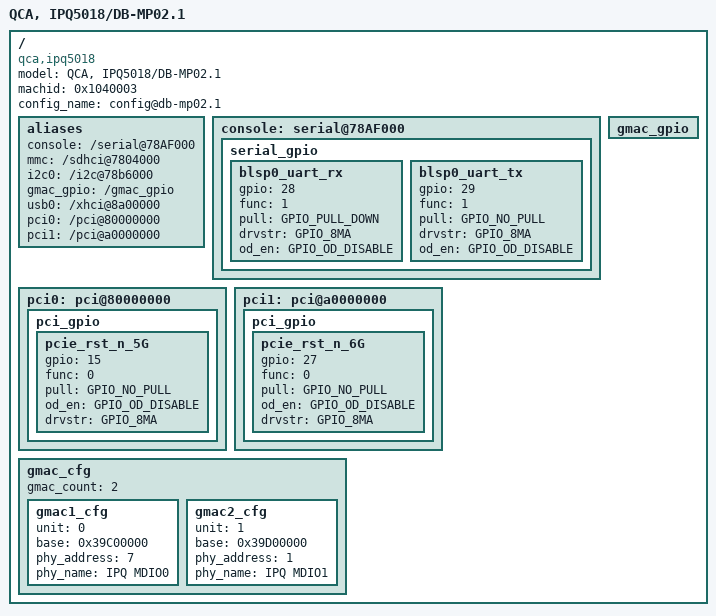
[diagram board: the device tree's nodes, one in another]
/*
 * Copyright (c) 2016-2020, The Linux Foundation. All rights reserved.
 *
 * This program is free software; you can redistribute it and/or modify
 * it under the terms of the GNU General Public License version 2 and
 * only version 2 as published by the Free Software Foundation.
 *
 * This program is distributed in the hope that it will be useful,
 * but WITHOUT ANY WARRANTY; without even the implied warranty of
 * MERCHANTABILITY or FITNESS FOR A PARTICULAR PURPOSE.  See the
 * GNU General Public License for more details.
 */

/dts-v1/;
#include "ipq5018-soc.dtsi"
/ {
	model ="QCA, IPQ5018/DB-MP02.1";
	compatible = "qca,ipq5018", "qca,ipq5018-db-mp02.1";
	machid = <0x1040003>;
	config_name = "config@db-mp02.1";

	aliases {
		console = "/serial@78AF000";
		mmc = "/sdhci@7804000";
		i2c0 = "/i2c@78b6000";
		gmac_gpio = "/gmac_gpio";
		usb0 = "/xhci@8a00000";
		pci0 = "/pci@80000000";
		pci1 = "/pci@a0000000";
	};

	console: serial@78AF000 {
		status = "ok";
		serial_gpio {
			blsp0_uart_rx {
				gpio = <28>;
				func = <1>;
				pull = <GPIO_PULL_DOWN>;
				drvstr = <GPIO_8MA>;
				od_en = <GPIO_OD_DISABLE>;
			};
			blsp0_uart_tx {
				gpio = <29>;
				func = <1>;
				pull = <GPIO_NO_PULL>;
				drvstr = <GPIO_8MA>;
				od_en = <GPIO_OD_DISABLE>;
			};
		};
	};

	pci0: pci@80000000 {
		status = "ok";
		pci_gpio {
			pcie_rst_n_5G {
				gpio = <15>;
				func = <0>;
				pull = <GPIO_NO_PULL>;
				od_en = <GPIO_OD_DISABLE>;
				drvstr = <GPIO_8MA>;
			};
		};
	};

	pci1: pci@a0000000 {
		status = "ok";
		pci_gpio {
			pcie_rst_n_6G {
				gpio = <27>;
				func = <0>;
				pull = <GPIO_NO_PULL>;
				od_en = <GPIO_OD_DISABLE>;
				drvstr = <GPIO_8MA>;
			};
		};
	};

	gmac_cfg {
		gmac_count = <2>;

		gmac1_cfg {
			unit = <0>;
			base = <0x39C00000>;
			phy_address = <7>;
			phy_name = "IPQ MDIO0";
		};

		gmac2_cfg {
			unit = <1>;
			base = <0x39D00000>;
			phy_address = <1>;
			phy_name = "IPQ MDIO1";
		};
	};

	gmac_gpio{};

};
